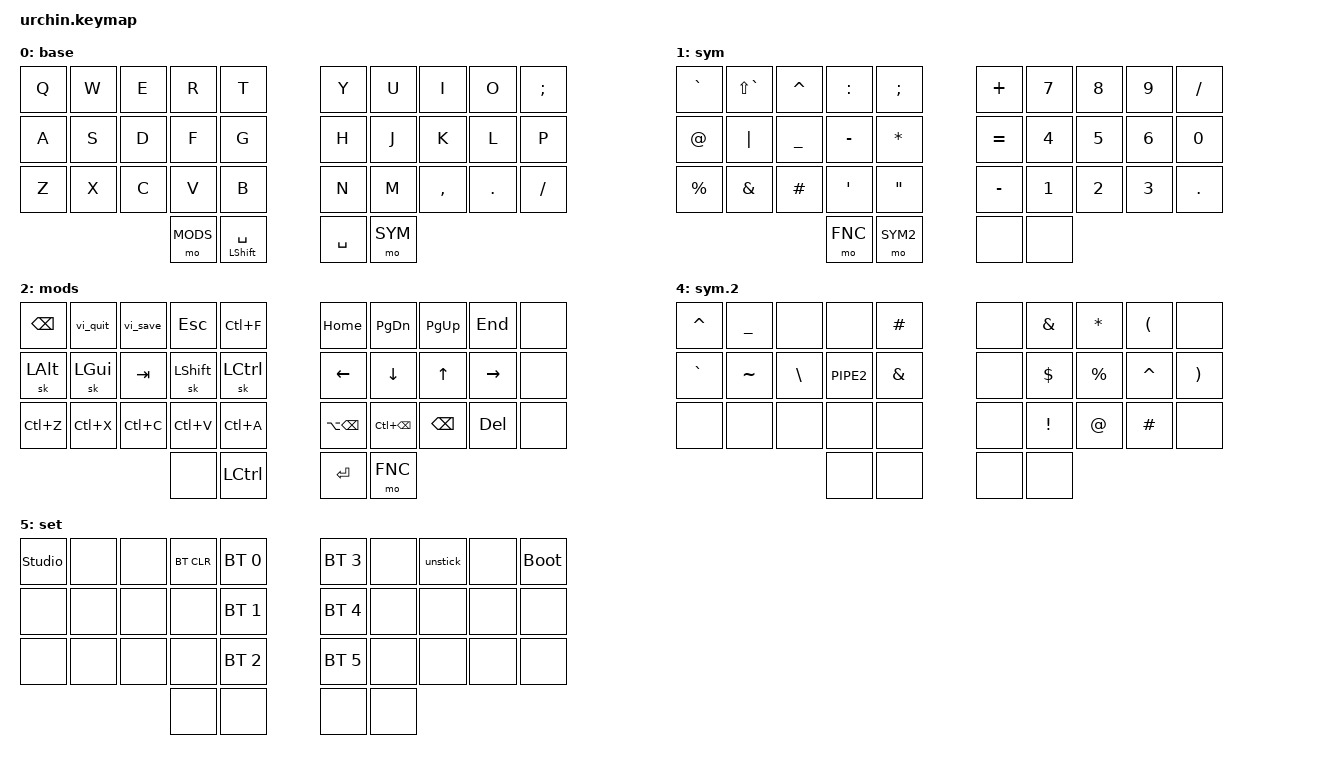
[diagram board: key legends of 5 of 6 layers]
/*
 * Copyright (c) 2025 moon0440
 *
 * SPDX-License-Identifier: MIT
 */

#include <behaviors.dtsi>
#include <dt-bindings/zmk/bt.h>
#include <dt-bindings/zmk/keys.h>
#include <dt-bindings/zmk/outputs.h>

// Layer definitions

#define BASE 0
#define SYM 1
#define MODS 2
#define FNC 3
#define SYM2 4
#define ACCENT 5
#define SETTINGS 6

// -----------------

&sk {
    // don't release mods on other mods presses

    ignore-modifiers;
};

/ {
    behaviors {
        // Enables holding the first mod-tap key
        // by performing a tap-release-hold sequence.
        // To use it: "&qt KEYCODE1 KEYCODE2"

        qt: quick_tap {
            compatible = "zmk,behavior-hold-tap";
            label = "QUICK_TAP";
            #binding-cells = <2>;
            flavor = "hold-preferred";
            tapping-term-ms = <200>;
            quick-tap-ms = <200>;
            bindings = <&kp>, <&kp>;
        };
    };

    macros {
        // sometimes my device thinks a modifier is being held down
        // pressing all modifiers fixes it.

        unstick: unstick {
            label = "ZM_unstick";
            compatible = "zmk,behavior-macro";
            #binding-cells = <0>;
            bindings = <&kp LSHIFT &kp RSHIFT &kp LCTRL &kp RCTRL &kp LALT &kp RALT &kp LGUI &kp RGUI>;
        }; 
	macros {
	        vi_quit: vi_quit {
	            compatible = "zmk,behavior-macro";
	            #binding-cells = <0>;
	            bindings
	                = <&macro_tap &kp COLON>
	                , <&macro_tap &kp Q>
	                , <&macro_tap &kp ENTER>
	                ;
	        }; 
		vi_save: vi_save {
	            compatible = "zmk,behavior-macro";
	            #binding-cells = <0>;
	            bindings
	                = <&macro_tap &kp COLON> 
			, <&macro_tap &kp W>
	                , <&macro_tap &kp ENTER>
	                ;
	        };
    };
    };

    combos {
        compatible = "zmk,combos";
        combo_LEFT_PARENTHESIS {
            timeout-ms = <50>;
            key-positions = <1 2>;
            bindings = <&kp LEFT_PARENTHESIS>; 
            layers = <SYM>;
            slow-release;
        }; 
        combo_RIGHT_PARENTHESIS {
            timeout-ms = <50>;
            key-positions = <2 3>;
            bindings = <&kp RIGHT_PARENTHESIS>; 
            layers = <SYM>;
            slow-release;
        };
        combo_LESS_THAN {
            timeout-ms = <50>;
            key-positions = <3 4>;
            bindings = <&kp LESS_THAN>; 
            layers = <SYM>;
            slow-release;
        };
        combo_LEFT_BRACKET {
            timeout-ms = <50>;
            key-positions = <11 12>;
            bindings = <&kp LEFT_BRACKET>; 
            layers = <SYM>;
            slow-release;
        }; 
        combo_RIGHT_BRACKET {
            timeout-ms = <50>;
            key-positions = <12 13>;
            bindings = <&kp RIGHT_BRACKET>; 
            layers = <SYM>;
            slow-release;
        };
        combo_GREATER_THAN {
            timeout-ms = <50>;
            key-positions = <13 14>;
            bindings = <&kp GREATER_THAN>; 
            layers = <SYM>;
            slow-release;
        };
        combo_LEFT_BRACE {
            timeout-ms = <50>;
            key-positions = <21 22>;
            bindings = <&kp LEFT_BRACE>; 
            layers = <SYM>;
            slow-release;
        };
        combo_RIGHT_BRACE {
            timeout-ms = <50>;
            key-positions = <22 23>;
            bindings = <&kp RIGHT_BRACE>; 
            layers = <SYM>;
            slow-release;
        };

    };

    keymap {
        compatible = "zmk,keymap";

        default_layer {
		label = "base";
		bindings = <
			&kp Q        &kp W        &kp E        &kp R        &kp T                       &kp Y        &kp U        &kp I        &kp O        &kp SEMICOLON 
			&kp A        &kp S        &kp D        &kp F        &kp G                       &kp H        &kp J        &kp K        &kp L        &kp P
			&kp Z        &kp X        &kp C        &kp V        &kp B                       &kp N        &kp M        &kp COMMA    &kp DOT      &kp SLASH
							       &mo MODS      &qt LSHIFT SPACE           &kp SPACE    &mo SYM
		>;
        };

        sym_layer {
		label = "sym";
		bindings = <
			&kp GRAVE &kp LS(GRAVE) &kp CARET &kp COLON &kp SEMICOLON		         &kp PLUS &kp N7 &kp N8 &kp N9 &kp SLASH
			&kp AT_SIGN &kp PIPE &kp UNDERSCORE &kp MINUS &kp ASTERISK          	         &kp EQUAL &kp N4 &kp N5 &kp N6 &kp N0
			&kp PERCENT &kp AMPERSAND &kp HASH &kp SINGLE_QUOTE &kp DOUBLE_QUOTES 	         &kp MINUS &kp N1 &kp N2 &kp N3 &kp DOT 
								&mo FNC  &mo SYM2                        &none &none
		>;
        };

        mods_layer {
		label = "mods";
		bindings = <
			&kp BSPC  &vi_quit &vi_save  &kp ESC  &kp LC(F)    	&kp HOME  &kp PAGE_DOWN &kp PAGE_UP &kp END &none
			&sk LALT &sk LGUI  &kp TAB  &sk LSHIFT  &sk LCTRL 		&kp LEFT &kp DOWN  &kp UP   &kp RIGHT   &none
			&kp LC(Z)  &kp LC(X) &kp LC(C) &kp LC(V) &kp LC(A)      &kp LA(BSPC) &kp LC(BSPC) &kp BSPC &kp DELETE  &none
							&none &kp LCTRL        &kp ENTER  &mo FNC 
		>;
        };

        fnc_layer {
		label = "fnc";
		bindings = <
			&studio_unlock &none &bt BT_CLR &none &none               &kp F12 &kp F7 &kp F8 &kp F9 &kp PRINTSCREEN
			&none &none &none &none &none                             &kp F11 &kp F4 &kp F5 &kp F6 &none &none
			&bootloader &none &none &none &none	                  &kp F10  &kp F1 &kp F2 &kp F3 &bootloader
					    &none &none                           &none &none  
		>;
        };

	symbols_2_layer {
		label = "sym.2";
		bindings = <
			&kp CARET &kp UNDERSCORE  &none &none &kp HASH                    &none &kp AMPERSAND &kp ASTERISK &kp LEFT_PARENTHESIS &none 
			&kp GRAVE &kp TILDE &kp BACKSLASH &kp PIPE2 &kp AMPERSAND         &none &kp DOLLAR &kp PERCENT &kp CARET &kp RIGHT_PARENTHESIS
			&none &none &none &none &none		                          &none &kp EXCLAMATION &kp AT_SIGN &kp HASH &none
								&none &none        	    &none &none 
		>;
	};

        settings_layer {
		label = "set";
		bindings = <
			&studio_unlock    &none    &none    &bt BT_CLR    &bt BT_SEL 0    &bt BT_SEL 3    &none     &unstick    &none    &bootloader
			&none             &none    &none    &none         &bt BT_SEL 1    &bt BT_SEL 4    &none     &none       &none    &none
			&none             &none    &none    &none         &bt BT_SEL 2    &bt BT_SEL 5    &none     &none       &none    &none
							    &none         &none           &none           &none
		>;
        };
    };
};
